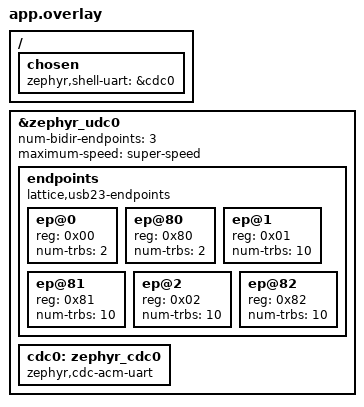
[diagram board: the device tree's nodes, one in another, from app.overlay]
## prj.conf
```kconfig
CONFIG_ASSERT=y
CONFIG_BOOT_BANNER=n
CONFIG_GPIO=n
CONFIG_I2C_SHELL=y
CONFIG_KERNEL_SHELL=y
CONFIG_LOG=y
CONFIG_LOG_MODE_MINIMAL=y
CONFIG_NET_BUF_POOL_USAGE=y
CONFIG_SERIAL=y
CONFIG_SHELL=y
CONFIG_SPI=n
CONFIG_UART_LINE_CTRL=y
CONFIG_UDC_BUF_COUNT=32
CONFIG_UDC_DRIVER_LOG_LEVEL_INF=y
CONFIG_USBD_CDC_ACM_CLASS=y
CONFIG_USBD_CDC_ACM_LOG_LEVEL_WRN=y
CONFIG_USBD_LOG_LEVEL_INF=y
CONFIG_USBD_SHELL=y
CONFIG_XIP=y
```

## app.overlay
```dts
/ {
	chosen {
		zephyr,shell-uart = &cdc0;
	};
};

&zephyr_udc0 {
	/* IN and OUT counting together as one endpoint */
	num-bidir-endpoints = <3>;

	endpoints {
		compatible = "lattice,usb23-endpoints";
		#address-cells = <1>;
		#size-cells = <0>;

		ep@0 {
			reg = <0x00>;
			num-trbs = <2>;
		};

		ep@80 {
			reg = <0x80>;
			num-trbs = <2>;
		};

		ep@1 {
			reg = <0x01>;
			num-trbs = <10>;
		};

		ep@81 {
			reg = <0x81>;
			num-trbs = <10>;
		};

		ep@2 {
			reg = <0x02>;
			num-trbs = <10>;
		};

		ep@82 {
			reg = <0x82>;
			num-trbs = <10>;
		};
	};

	/* full-speed: 12 Mhz, high-speed: 480 Mhz, super-speed: 5000 Mhz */
	maximum-speed = "super-speed";

	cdc0: zephyr_cdc0 {
		compatible = "zephyr,cdc-acm-uart";
		status = "okay";
	};
};
```

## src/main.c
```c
#include <zephyr/kernel.h>
#include <zephyr/devicetree.h>
#include <zephyr/drivers/usb/udc.h>
#include <zephyr/drivers/video.h>
#include <zephyr/usb/usbd.h>
#include <zephyr/usb/bos.h>

#include <zephyr/logging/log.h>
LOG_MODULE_REGISTER(main, LOG_LEVEL_DBG);

USBD_DEVICE_DEFINE(my_usbd, DEVICE_DT_GET(DT_NODELABEL(zephyr_udc0)), 0x1209, 0x0001);

int main(void)
{
	int err = 0;
#if 0
	USBD_DEVICE_QUALIFIER_DEFINE(my_usbd_dev_qualifier);
	err |= usbd_add_descriptor(&my_usbd, &my_usbd_dev_qualifier);
	__ASSERT_NO_MSG(err == 0);
#endif
	USBD_BOS_DEFINE(my_usbd_bos);
	err |= usbd_add_descriptor(&my_usbd, &my_usbd_bos);
	__ASSERT_NO_MSG(err == 0);

	USBD_DESC_LANG_DEFINE(my_usbd_lang);
	err |= usbd_add_descriptor(&my_usbd, &my_usbd_lang);
	__ASSERT_NO_MSG(err == 0);

	USBD_DESC_MANUFACTURER_DEFINE(my_usbd_manufacturer, "tinyVision.ai");
	err |= usbd_add_descriptor(&my_usbd, &my_usbd_manufacturer);
	__ASSERT_NO_MSG(err == 0);

	USBD_DESC_PRODUCT_DEFINE(my_usbd_product, "tinyCLUNX33");
	err |= usbd_add_descriptor(&my_usbd, &my_usbd_product);
	__ASSERT_NO_MSG(err == 0);
#if 0
	USBD_DESC_SERIAL_NUMBER_DEFINE(my_usbd_serial_number);
	err |= usbd_add_descriptor(&my_usbd, &my_usbd_serial_number);
	__ASSERT_NO_MSG(err == 0);
#endif
	USBD_CONFIGURATION_DEFINE(my_usbd_config, USB_SCD_SELF_POWERED, 100);
	err |= usbd_add_configuration(&my_usbd, &my_usbd_config);
	__ASSERT_NO_MSG(err == 0);

	err |= usbd_register_class(&my_usbd, "cdc_acm_0", 1);
	__ASSERT_NO_MSG(err == 0);

	err |= usbd_init(&my_usbd);
	__ASSERT_NO_MSG(err == 0);

	err |= usbd_enable(&my_usbd);
	__ASSERT_NO_MSG(err == 0);

	k_sleep(K_FOREVER);
	return 0;
}
```
